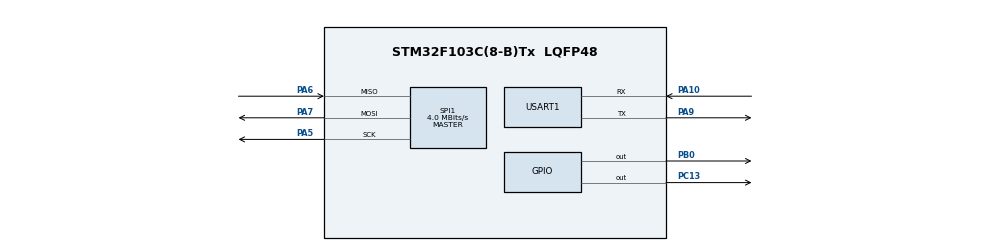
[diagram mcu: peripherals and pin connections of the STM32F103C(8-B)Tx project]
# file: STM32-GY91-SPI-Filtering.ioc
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Dma.MEMTOMEM.0.Direction=DMA_MEMORY_TO_MEMORY
Dma.MEMTOMEM.0.Instance=DMA1_Channel1
Dma.MEMTOMEM.0.MemDataAlignment=DMA_MDATAALIGN_BYTE
Dma.MEMTOMEM.0.MemInc=DMA_MINC_ENABLE
Dma.MEMTOMEM.0.Mode=DMA_NORMAL
Dma.MEMTOMEM.0.PeriphDataAlignment=DMA_PDATAALIGN_BYTE
Dma.MEMTOMEM.0.PeriphInc=DMA_PINC_ENABLE
Dma.MEMTOMEM.0.Priority=DMA_PRIORITY_LOW
Dma.MEMTOMEM.1.Direction=DMA_MEMORY_TO_MEMORY
Dma.MEMTOMEM.1.Instance=DMA1_Channel2
Dma.MEMTOMEM.1.MemDataAlignment=DMA_MDATAALIGN_BYTE
Dma.MEMTOMEM.1.MemInc=DMA_MINC_ENABLE
Dma.MEMTOMEM.1.Mode=DMA_NORMAL
Dma.MEMTOMEM.1.PeriphDataAlignment=DMA_PDATAALIGN_BYTE
Dma.MEMTOMEM.1.PeriphInc=DMA_PINC_ENABLE
Dma.MEMTOMEM.1.Priority=DMA_PRIORITY_LOW
Dma.Request0=MEMTOMEM
Dma.Request1=MEMTOMEM
Mcu.Family=STM32F1
Mcu.Name=STM32F103C(8-B)Tx
Mcu.Package=LQFP48
NVIC.PriorityGroup=NVIC_PRIORITYGROUP_4
PA10.Mode=Asynchronous
PA10.Signal=USART1_RX
PA13.Mode=Serial_Wire
PA13.Signal=SYS_JTMS-SWDIO
PA14.Mode=Serial_Wire
PA14.Signal=SYS_JTCK-SWCLK
PA5.Mode=Full_Duplex_Master
PA5.Signal=SPI1_SCK
PA6.Mode=Full_Duplex_Master
PA6.Signal=SPI1_MISO
PA7.Mode=Full_Duplex_Master
PA7.Signal=SPI1_MOSI
PA9.Mode=Asynchronous
PA9.Signal=USART1_TX
PB0.PinState=GPIO_PIN_SET
PB0.Signal=GPIO_Output
PC13-TAMPER-RTC.Signal=GPIO_Output
PD0-OSC_IN.Mode=HSE-External-Oscillator
PD0-OSC_IN.Signal=RCC_OSC_IN
PD1-OSC_OUT.Mode=HSE-External-Oscillator
PD1-OSC_OUT.Signal=RCC_OSC_OUT
ProjectManager.HeapSize=0x200
ProjectManager.StackSize=0x400
ProjectManager.TargetToolchain=STM32CubeIDE
RCC.APB1Freq_Value=8000000
RCC.APB2Freq_Value=8000000
SPI1.CalculateBaudRate=4.0 MBits/s
SPI1.Direction=SPI_DIRECTION_2LINES
SPI1.Mode=SPI_MODE_MASTER
SPI1.VirtualType=VM_MASTER
USART1.VirtualMode=VM_ASYNC
board=custom

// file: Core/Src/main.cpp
/* USER CODE BEGIN Header */
/**
  ******************************************************************************
  * @file           : main.c
  * @brief          : Main program body
  ******************************************************************************
  * @attention
  *
  * Copyright (c) 2024 STMicroelectronics.
  * All rights reserved.
  *
  * This software is licensed under terms that can be found in the LICENSE file
  * in the root directory of this software component.
  * If no LICENSE file comes with this software, it is provided AS-IS.
  *
  ******************************************************************************
  */
/* USER CODE END Header */
#include "main.h"
#include "dma.h"
#include "spi.h"
#include "usart.h"
#include "gpio.h"

/* USER CODE BEGIN Includes */

#include <stdio.h>

#include <MPU9250.h>

#include "sensors/sensors_gy91.h"

#include "filtering/kalman-filtering/kalman_filtering.h"
#include "filtering/calibration-filtering/calibration.h"

/* USER CODE END Includes */

void SystemClock_Config(void);

int main(void)
{

  /* MCU Configuration--------------------------------------------------------*/

  /* Reset of all peripherals, Initializes the Flash interface and the Systick. */
  HAL_Init();

  /* Configure the system clock */
  SystemClock_Config();

  /* Initialize all configured peripherals */
  MX_DMA_Init();
  MX_GPIO_Init();
  MX_SPI1_Init();
  MX_USART1_UART_Init();
  /* USER CODE BEGIN 2 */
  printf("STM32 Initialized!\n");

  int status = sensor_gy91_init();
  if (status != SENSOR_OK){
	  printf ("Error initializing!\n");
  }

  /* USER CODE END 2 */
  /* Infinite loop */
  /* USER CODE BEGIN WHILE */
  GPIO_PinState led_state = GPIO_PIN_RESET;
  HAL_GPIO_WritePin(GPIOC, GPIO_PIN_13, led_state);

    /* USER CODE END WHILE */

    /* USER CODE BEGIN 3 */

    filtering_main();
//  calibration_main();

  printf("Program end!\n");
  while(1);
  /* USER CODE END 3 */
}

void SystemClock_Config(void)
{
  RCC_OscInitTypeDef RCC_OscInitStruct = {0};
  RCC_ClkInitTypeDef RCC_ClkInitStruct = {0};

  /** Initializes the RCC Oscillators according to the specified parameters
  * in the RCC_OscInitTypeDef structure.
  */
  RCC_OscInitStruct.OscillatorType = RCC_OSCILLATORTYPE_HSI;
  RCC_OscInitStruct.HSIState = RCC_HSI_ON;
  RCC_OscInitStruct.HSICalibrationValue = RCC_HSICALIBRATION_DEFAULT;
  RCC_OscInitStruct.PLL.PLLState = RCC_PLL_NONE;
  if (HAL_RCC_OscConfig(&RCC_OscInitStruct) != HAL_OK)
  {
    Error_Handler();
  }

  /** Initializes the CPU, AHB and APB buses clocks
  */
  RCC_ClkInitStruct.ClockType = RCC_CLOCKTYPE_HCLK|RCC_CLOCKTYPE_SYSCLK
                              |RCC_CLOCKTYPE_PCLK1|RCC_CLOCKTYPE_PCLK2;
  RCC_ClkInitStruct.SYSCLKSource = RCC_SYSCLKSOURCE_HSI;
  RCC_ClkInitStruct.AHBCLKDivider = RCC_SYSCLK_DIV1;
  RCC_ClkInitStruct.APB1CLKDivider = RCC_HCLK_DIV1;
  RCC_ClkInitStruct.APB2CLKDivider = RCC_HCLK_DIV1;

  if (HAL_RCC_ClockConfig(&RCC_ClkInitStruct, FLASH_LATENCY_0) != HAL_OK)
  {
    Error_Handler();
  }
}

void Error_Handler(void)
{
  __disable_irq();
  while (1)
  {
  }
}
